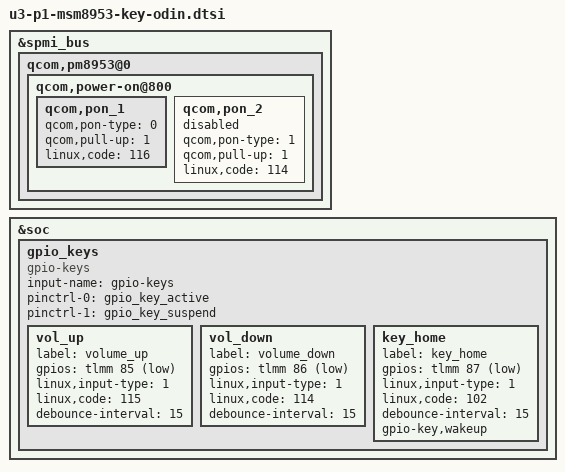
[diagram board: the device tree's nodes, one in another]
/*rewrite msm8953-qrd.dtsi*/


/*rewrite msm-pm8953.dtsi*/
&spmi_bus {
	qcom,pm8953@0 {
		qcom,power-on@800 {
			qcom,pon_1 {
				qcom,pon-type = <0>;
				qcom,pull-up = <1>;
				linux,code = <116>;
			};
			qcom,pon_2 {
				qcom,pon-type = <1>;
				qcom,pull-up = <1>;
				linux,code = <114>;
				status = "disable";
			};

		};
	};
};

&soc {
	gpio_keys {
		compatible = "gpio-keys";
		input-name = "gpio-keys";
		pinctrl-names = "tlmm_gpio_key_active","tlmm_gpio_key_suspend";
		pinctrl-0 = <&gpio_key_active>;
		pinctrl-1 = <&gpio_key_suspend>;

		vol_up {
			label = "volume_up";
			gpios = <&tlmm 85 0x1>;
			linux,input-type = <1>;
			linux,code = <115>;
			debounce-interval = <15>;
		};

		vol_down {
			label = "volume_down";
			gpios = <&tlmm 86 0x1>;
			linux,input-type = <1>;
			linux,code = <114>;
			debounce-interval = <15>;
		};
		key_home {
			label = "key_home";
			gpios = <&tlmm 87 0x1>;
			linux,input-type = <1>;
			linux,code = <102>;
			debounce-interval = <15>;
			gpio-key,wakeup;
		};
	};

};



